# iom480ae register map
Registers are 32-bit, access not given, no defined reset value unless marked. A register's access mark holds for its fields unless they carry their own. Addresses are absolute; registers are grouped by the start of their names; [hi:lo] are bit positions; 'fields as' and 'values as' point back to an identical list.

## TMR23
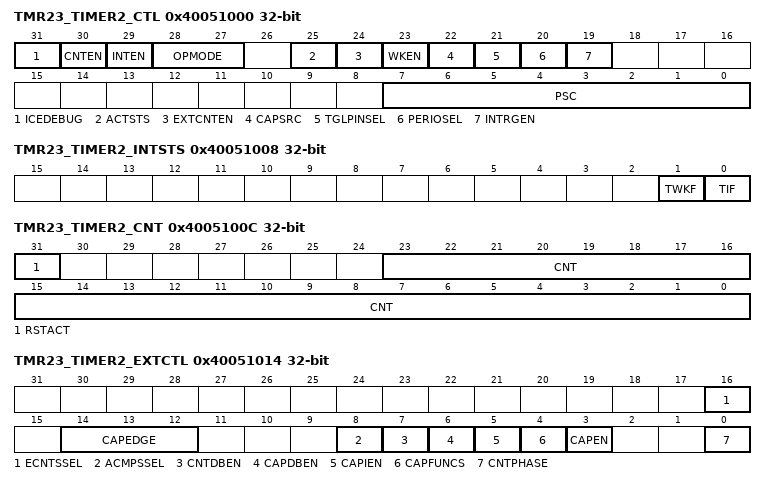
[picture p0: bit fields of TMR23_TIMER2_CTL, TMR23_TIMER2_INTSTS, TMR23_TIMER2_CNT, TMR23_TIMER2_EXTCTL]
0x40051000 TMR23_TIMER2_CTL
  [31] ICEDEBUG, [30] CNTEN, [29] INTEN, [28:27] OPMODE, [25] ACTSTS, [24] EXTCNTEN, [23] WKEN, [22] CAPSRC, [21] TGLPINSEL, [20] PERIOSEL, [19] INTRGEN, [7:0] PSC
0x40051004 TMR23_TIMER2_CMP
  [23:0] CMPDAT
0x40051008 TMR23_TIMER2_INTSTS
  [1] TWKF, [0] TIF
0x4005100C TMR23_TIMER2_CNT
  [31] RSTACT, [23:0] CNT
0x40051010 TMR23_TIMER2_CAP
  [23:0] CAPDAT
0x40051014 TMR23_TIMER2_EXTCTL
  [16] ECNTSSEL, [14:12] CAPEDGE, [8] ACMPSSEL, [7] CNTDBEN, [6] CAPDBEN, [5] CAPIEN, [4] CAPFUNCS, [3] CAPEN, [0] CNTPHASE
0x40051018 TMR23_TIMER2_EINTSTS
  [0] CAPIF
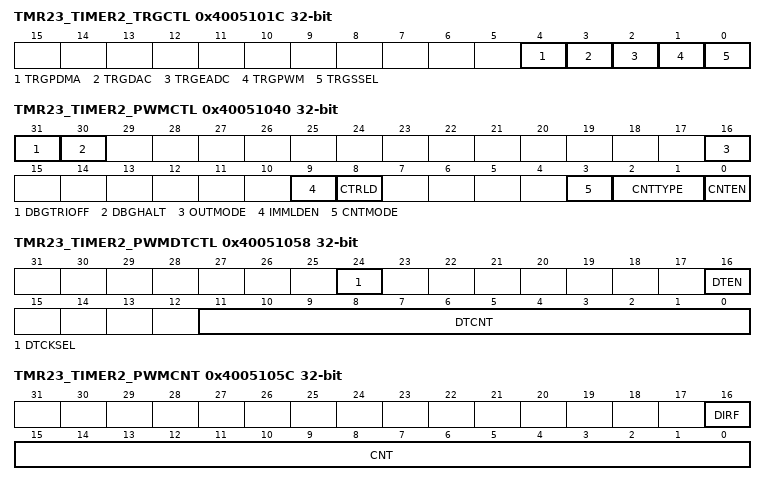
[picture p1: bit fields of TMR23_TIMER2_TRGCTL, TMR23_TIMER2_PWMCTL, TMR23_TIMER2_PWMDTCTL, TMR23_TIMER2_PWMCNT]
0x4005101C TMR23_TIMER2_TRGCTL
  [4] TRGPDMA, [3] TRGDAC, [2] TRGEADC, [1] TRGPWM, [0] TRGSSEL
0x40051020 TMR23_TIMER2_ALTCTL
  [0] FUNCSEL
0x40051040 TMR23_TIMER2_PWMCTL
  [31] DBGTRIOFF, [30] DBGHALT, [16] OUTMODE, [9] IMMLDEN, [8] CTRLD, [3] CNTMODE, [2:1] CNTTYPE, [0] CNTEN
0x40051044 TMR23_TIMER2_PWMCLKSRC
  [2:0] CLKSRC
0x40051048 TMR23_TIMER2_PWMCLKPSC
  [11:0] CLKPSC
0x4005104C TMR23_TIMER2_PWMCNTCLR
  [0] CNTCLR
0x40051050 TMR23_TIMER2_PWMPERIOD
  [15:0] PERIOD
0x40051054 TMR23_TIMER2_PWMCMPDAT
  [15:0] CMP
0x40051058 TMR23_TIMER2_PWMDTCTL
  [24] DTCKSEL, [16] DTEN, [11:0] DTCNT
0x4005105C TMR23_TIMER2_PWMCNT
  [16] DIRF, [15:0] CNT
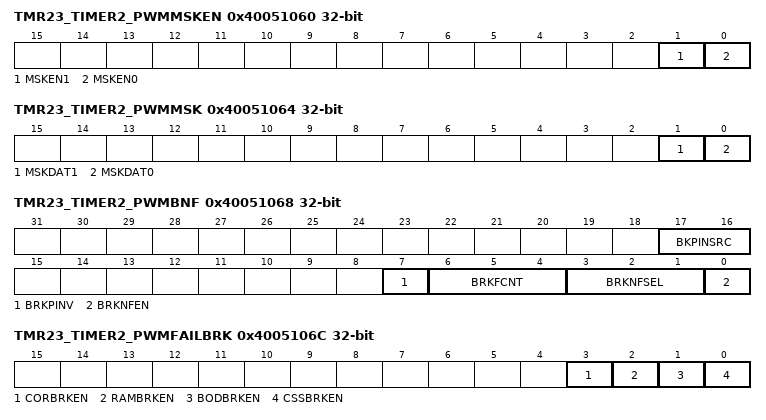
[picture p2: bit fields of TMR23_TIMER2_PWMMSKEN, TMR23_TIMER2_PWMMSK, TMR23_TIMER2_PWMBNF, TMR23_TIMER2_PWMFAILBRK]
0x40051060 TMR23_TIMER2_PWMMSKEN
  [1] MSKEN1, [0] MSKEN0
0x40051064 TMR23_TIMER2_PWMMSK
  [1] MSKDAT1, [0] MSKDAT0
0x40051068 TMR23_TIMER2_PWMBNF
  [17:16] BKPINSRC, [7] BRKPINV, [6:4] BRKFCNT, [3:1] BRKNFSEL, [0] BRKNFEN
0x4005106C TMR23_TIMER2_PWMFAILBRK
  [3] CORBRKEN, [2] RAMBRKEN, [1] BODBRKEN, [0] CSSBRKEN
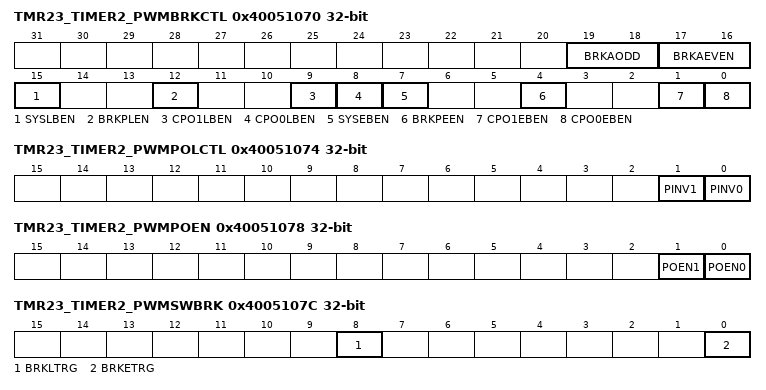
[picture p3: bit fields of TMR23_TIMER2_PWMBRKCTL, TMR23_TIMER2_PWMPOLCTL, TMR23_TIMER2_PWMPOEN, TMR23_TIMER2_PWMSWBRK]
0x40051070 TMR23_TIMER2_PWMBRKCTL
  [19:18] BRKAODD, [17:16] BRKAEVEN, [15] SYSLBEN, [12] BRKPLEN, [9] CPO1LBEN, [8] CPO0LBEN, [7] SYSEBEN, [4] BRKPEEN, [1] CPO1EBEN, [0] CPO0EBEN
0x40051074 TMR23_TIMER2_PWMPOLCTL
  [1] PINV1, [0] PINV0
0x40051078 TMR23_TIMER2_PWMPOEN
  [1] POEN1, [0] POEN0
0x4005107C TMR23_TIMER2_PWMSWBRK
  [8] BRKLTRG, [0] BRKETRG
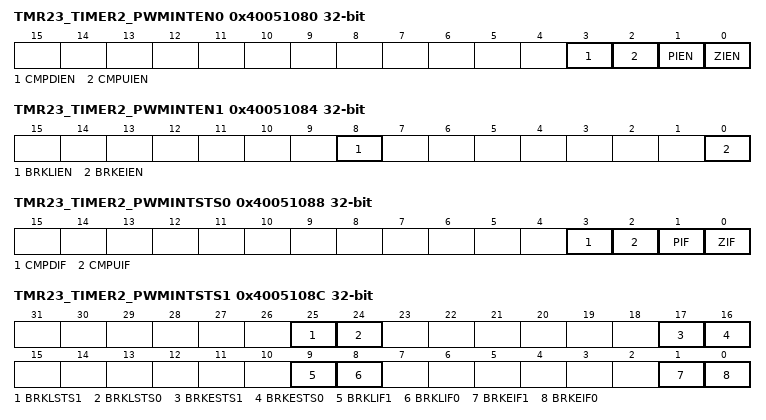
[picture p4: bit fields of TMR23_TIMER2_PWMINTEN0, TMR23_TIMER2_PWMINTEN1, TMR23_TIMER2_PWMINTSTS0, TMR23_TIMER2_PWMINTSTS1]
0x40051080 TMR23_TIMER2_PWMINTEN0
  [3] CMPDIEN, [2] CMPUIEN, [1] PIEN, [0] ZIEN
0x40051084 TMR23_TIMER2_PWMINTEN1
  [8] BRKLIEN, [0] BRKEIEN
0x40051088 TMR23_TIMER2_PWMINTSTS0
  [3] CMPDIF, [2] CMPUIF, [1] PIF, [0] ZIF
0x4005108C TMR23_TIMER2_PWMINTSTS1
  [25] BRKLSTS1, [24] BRKLSTS0, [17] BRKESTS1, [16] BRKESTS0, [9] BRKLIF1, [8] BRKLIF0, [1] BRKEIF1, [0] BRKEIF0
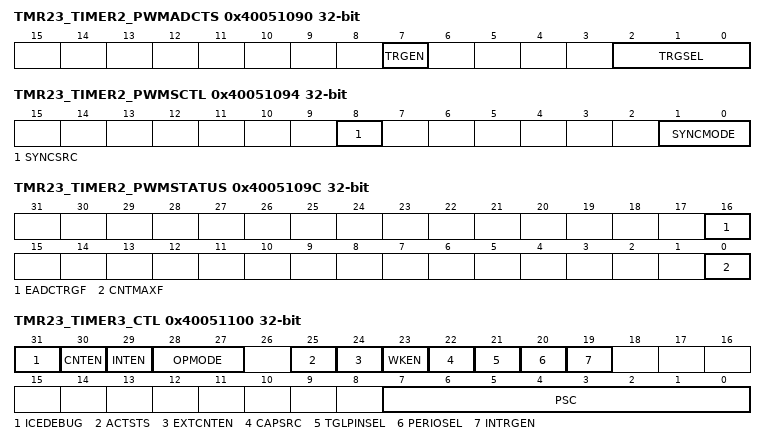
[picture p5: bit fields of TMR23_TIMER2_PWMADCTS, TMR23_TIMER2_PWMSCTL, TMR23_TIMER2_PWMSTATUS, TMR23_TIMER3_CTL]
0x40051090 TMR23_TIMER2_PWMADCTS
  [7] TRGEN, [2:0] TRGSEL
0x40051094 TMR23_TIMER2_PWMSCTL
  [8] SYNCSRC, [1:0] SYNCMODE
0x40051098 TMR23_TIMER2_PWMSTRG
  [0] STRGEN
0x4005109C TMR23_TIMER2_PWMSTATUS
  [16] EADCTRGF, [0] CNTMAXF
0x400510A0 TMR23_TIMER2_PWMPBUF
  [15:0] PBUF
0x400510A4 TMR23_TIMER2_PWMCMPBUF
  [15:0] CMPBUF
0x40051100 TMR23_TIMER3_CTL
  fields as TMR23_TIMER2_CTL
0x40051104 TMR23_TIMER3_CMP
  [23:0] CMPDAT
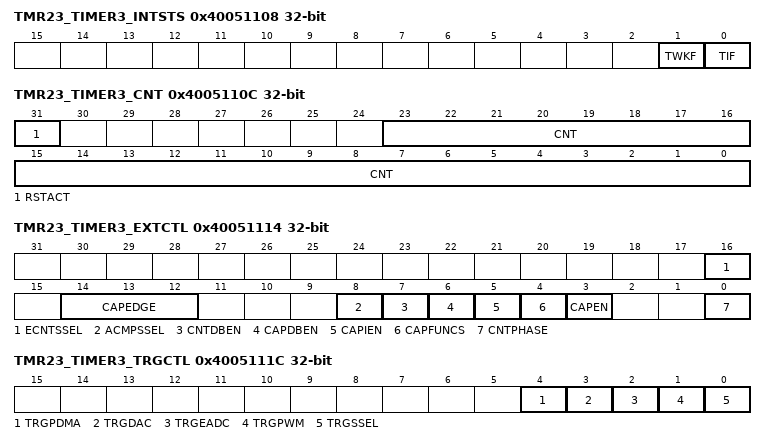
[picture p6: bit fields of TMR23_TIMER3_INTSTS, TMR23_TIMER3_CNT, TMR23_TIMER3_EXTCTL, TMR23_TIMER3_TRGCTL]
0x40051108 TMR23_TIMER3_INTSTS
  [1] TWKF, [0] TIF
0x4005110C TMR23_TIMER3_CNT
  [31] RSTACT, [23:0] CNT
0x40051110 TMR23_TIMER3_CAP
  [23:0] CAPDAT
0x40051114 TMR23_TIMER3_EXTCTL
  fields as TMR23_TIMER2_EXTCTL
0x40051118 TMR23_TIMER3_EINTSTS
  [0] CAPIF
0x4005111C TMR23_TIMER3_TRGCTL
  [4] TRGPDMA, [3] TRGDAC, [2] TRGEADC, [1] TRGPWM, [0] TRGSSEL
0x40051120 TMR23_TIMER3_ALTCTL
  [0] FUNCSEL
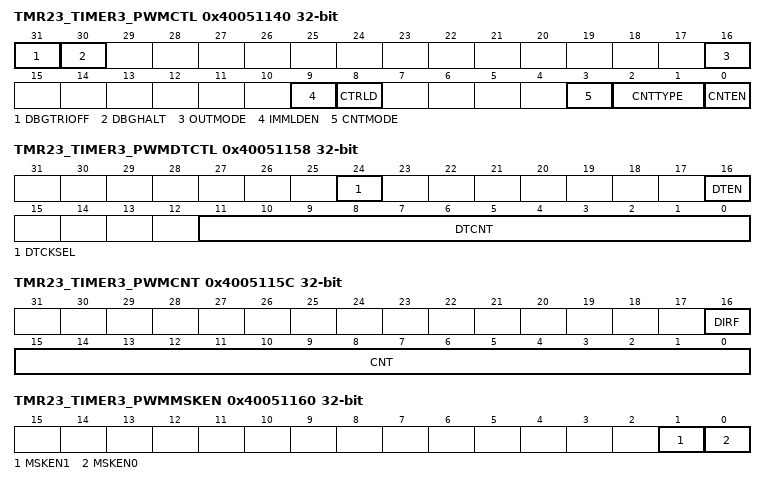
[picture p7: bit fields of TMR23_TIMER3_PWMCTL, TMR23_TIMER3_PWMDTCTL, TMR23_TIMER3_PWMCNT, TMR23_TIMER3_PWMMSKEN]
0x40051140 TMR23_TIMER3_PWMCTL
  fields as TMR23_TIMER2_PWMCTL
0x40051144 TMR23_TIMER3_PWMCLKSRC
  [2:0] CLKSRC
0x40051148 TMR23_TIMER3_PWMCLKPSC
  [11:0] CLKPSC
0x4005114C TMR23_TIMER3_PWMCNTCLR
  [0] CNTCLR
0x40051150 TMR23_TIMER3_PWMPERIOD
  [15:0] PERIOD
0x40051154 TMR23_TIMER3_PWMCMPDAT
  [15:0] CMP
0x40051158 TMR23_TIMER3_PWMDTCTL
  [24] DTCKSEL, [16] DTEN, [11:0] DTCNT
0x4005115C TMR23_TIMER3_PWMCNT
  [16] DIRF, [15:0] CNT
0x40051160 TMR23_TIMER3_PWMMSKEN
  [1] MSKEN1, [0] MSKEN0
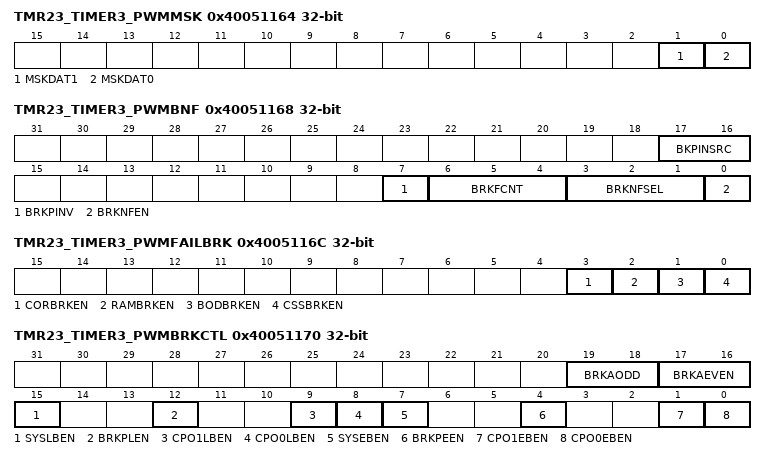
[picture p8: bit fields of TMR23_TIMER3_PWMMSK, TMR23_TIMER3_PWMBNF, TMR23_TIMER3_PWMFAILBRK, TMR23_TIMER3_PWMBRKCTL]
0x40051164 TMR23_TIMER3_PWMMSK
  [1] MSKDAT1, [0] MSKDAT0
0x40051168 TMR23_TIMER3_PWMBNF
  fields as TMR23_TIMER2_PWMBNF
0x4005116C TMR23_TIMER3_PWMFAILBRK
  [3] CORBRKEN, [2] RAMBRKEN, [1] BODBRKEN, [0] CSSBRKEN
0x40051170 TMR23_TIMER3_PWMBRKCTL
  fields as TMR23_TIMER2_PWMBRKCTL
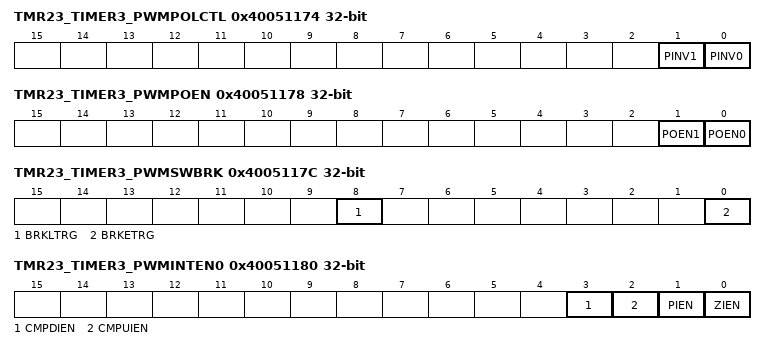
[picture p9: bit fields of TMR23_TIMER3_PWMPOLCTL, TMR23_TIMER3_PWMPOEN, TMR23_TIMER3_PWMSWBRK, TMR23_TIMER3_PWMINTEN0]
0x40051174 TMR23_TIMER3_PWMPOLCTL
  [1] PINV1, [0] PINV0
0x40051178 TMR23_TIMER3_PWMPOEN
  [1] POEN1, [0] POEN0
0x4005117C TMR23_TIMER3_PWMSWBRK
  [8] BRKLTRG, [0] BRKETRG
0x40051180 TMR23_TIMER3_PWMINTEN0
  [3] CMPDIEN, [2] CMPUIEN, [1] PIEN, [0] ZIEN
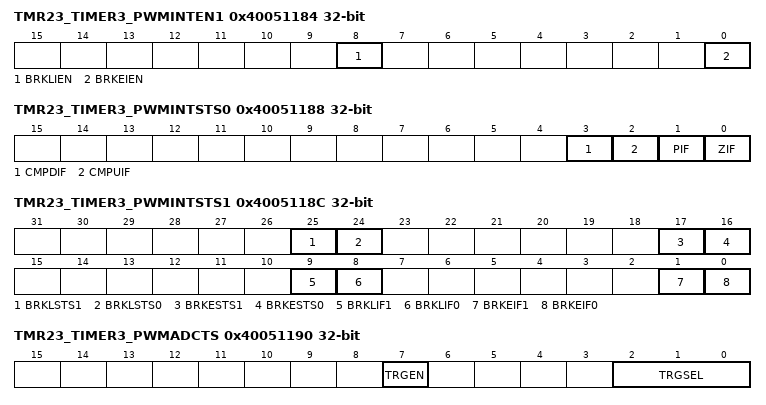
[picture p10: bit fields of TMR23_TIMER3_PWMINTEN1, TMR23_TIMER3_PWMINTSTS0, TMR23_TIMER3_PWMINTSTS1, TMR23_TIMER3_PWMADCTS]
0x40051184 TMR23_TIMER3_PWMINTEN1
  [8] BRKLIEN, [0] BRKEIEN
0x40051188 TMR23_TIMER3_PWMINTSTS0
  [3] CMPDIF, [2] CMPUIF, [1] PIF, [0] ZIF
0x4005118C TMR23_TIMER3_PWMINTSTS1
  fields as TMR23_TIMER2_PWMINTSTS1
0x40051190 TMR23_TIMER3_PWMADCTS
  [7] TRGEN, [2:0] TRGSEL
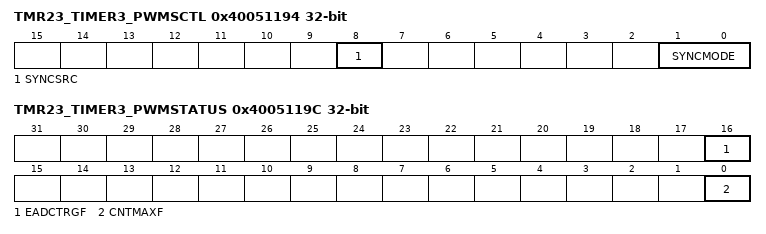
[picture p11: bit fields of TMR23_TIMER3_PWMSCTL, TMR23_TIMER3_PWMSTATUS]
0x40051194 TMR23_TIMER3_PWMSCTL
  [8] SYNCSRC, [1:0] SYNCMODE
0x4005119C TMR23_TIMER3_PWMSTATUS
  [16] EADCTRGF, [0] CNTMAXF
0x400511A0 TMR23_TIMER3_PWMPBUF
  [15:0] PBUF
0x400511A4 TMR23_TIMER3_PWMCMPBUF
  [15:0] CMPBUF
